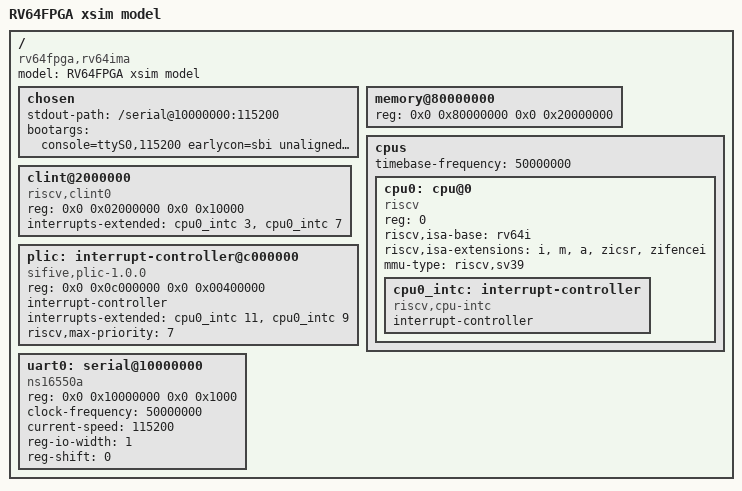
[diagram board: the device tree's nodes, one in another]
/dts-v1/;

/ {
  model = "RV64FPGA xsim model";
  compatible = "rv64fpga,rv64ima";
  #address-cells = <2>;
  #size-cells = <2>;

  chosen {
    stdout-path = "/serial@10000000:115200";
    bootargs = "console=ttyS0,115200 earlycon=sbi unaligned_scalar_speed=slow";
  };

  memory@80000000 {
    device_type = "memory";
    /* Use a conservative 512 MiB subset of the populated DDR3 capacity. */
    reg = <0x0 0x80000000 0x0 0x20000000>;
  };

  cpus {
    #address-cells = <1>;
    #size-cells = <0>;
    timebase-frequency = <50000000>;

    cpu0: cpu@0 {
      device_type = "cpu";
      compatible = "riscv";
      reg = <0>;
      status = "okay";
      riscv,isa-base = "rv64i";
      riscv,isa-extensions = "i", "m", "a", "zicsr", "zifencei";
      mmu-type = "riscv,sv39";

      cpu0_intc: interrupt-controller {
        compatible = "riscv,cpu-intc";
        #interrupt-cells = <1>;
        interrupt-controller;
      };
    };
  };

  clint@2000000 {
    compatible = "riscv,clint0";
    reg = <0x0 0x02000000 0x0 0x10000>;
    interrupts-extended = <&cpu0_intc 3>, <&cpu0_intc 7>;
  };

  plic: interrupt-controller@c000000 {
    compatible = "sifive,plic-1.0.0";
    reg = <0x0 0x0c000000 0x0 0x00400000>;
    #interrupt-cells = <1>;
    interrupt-controller;
    interrupts-extended = <&cpu0_intc 11>, <&cpu0_intc 9>;
    riscv,max-priority = <7>;
  };

  uart0: serial@10000000 {
    compatible = "ns16550a";
    reg = <0x0 0x10000000 0x0 0x1000>;
    clock-frequency = <50000000>;
    current-speed = <115200>;
    reg-io-width = <1>;
    reg-shift = <0>;
    status = "okay";
  };
};
